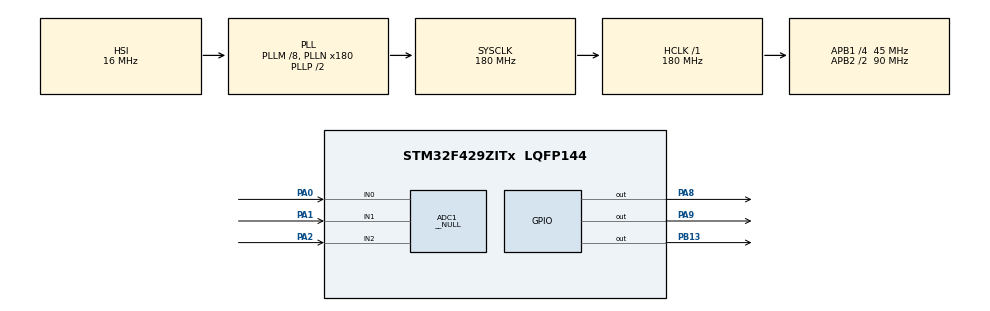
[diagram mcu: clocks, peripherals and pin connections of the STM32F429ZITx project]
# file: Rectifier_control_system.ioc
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ADC1.Channel-0\#ChannelRegularConversion=ADC_CHANNEL_0
ADC1.Channel-3\#ChannelRegularConversion=ADC_CHANNEL_1
ADC1.Channel-4\#ChannelRegularConversion=ADC_CHANNEL_2
ADC1.ContinuousConvMode=ENABLE
ADC1.DMAContinuousRequests=ENABLE
ADC1.EOCSelection=ADC_EOC_SEQ_CONV
ADC1.EnableAnalogWatchDog=true
ADC1.HighThreshold=2189
ADC1.ITMode=ENABLE
ADC1.InjNumberOfConversion=0
ADC1.LowThreshold=2154
ADC1.Mode=__NULL
ADC1.NbrOfConversion=3
ADC1.NbrOfConversionFlag=1
ADC1.Rank-0\#ChannelRegularConversion=1
ADC1.Rank-3\#ChannelRegularConversion=2
ADC1.Rank-4\#ChannelRegularConversion=3
ADC1.SamplingTime-0\#ChannelRegularConversion=ADC_SAMPLETIME_28CYCLES
ADC1.SamplingTime-3\#ChannelRegularConversion=ADC_SAMPLETIME_28CYCLES
ADC1.SamplingTime-4\#ChannelRegularConversion=ADC_SAMPLETIME_28CYCLES
ADC1.ScanConvMode=ENABLE
ADC1.WatchdogMode=ADC_ANALOGWATCHDOG_ALL_REG
ADC1.master=1
Dma.ADC1.0.Direction=DMA_PERIPH_TO_MEMORY
Dma.ADC1.0.FIFOMode=DMA_FIFOMODE_DISABLE
Dma.ADC1.0.Instance=DMA2_Stream0
Dma.ADC1.0.MemDataAlignment=DMA_MDATAALIGN_HALFWORD
Dma.ADC1.0.MemInc=DMA_MINC_ENABLE
Dma.ADC1.0.Mode=DMA_CIRCULAR
Dma.ADC1.0.PeriphDataAlignment=DMA_PDATAALIGN_HALFWORD
Dma.ADC1.0.PeriphInc=DMA_PINC_DISABLE
Dma.ADC1.0.Priority=DMA_PRIORITY_LOW
Dma.Request0=ADC1
Mcu.Family=STM32F4
Mcu.Name=STM32F429ZITx
Mcu.Package=LQFP144
NVIC.ADC_IRQn=true\:0\:0\:false\:false\:true\:true\:true\:true
NVIC.DMA2_Stream0_IRQn=true\:0\:0\:false\:false\:true\:false\:true\:true
NVIC.PriorityGroup=NVIC_PRIORITYGROUP_4
PA0/WKUP.Signal=ADCx_IN0
PA1.Signal=ADCx_IN1
PA13.Mode=Serial_Wire
PA13.Signal=SYS_JTMS-SWDIO
PA14.Mode=Serial_Wire
PA14.Signal=SYS_JTCK-SWCLK
PA2.Signal=ADCx_IN2
PA8.GPIO_PuPd=GPIO_PULLDOWN
PA8.GPIO_Speed=GPIO_SPEED_FREQ_HIGH
PA8.Signal=GPIO_Output
PA9.GPIO_PuPd=GPIO_PULLDOWN
PA9.GPIO_Speed=GPIO_SPEED_FREQ_HIGH
PA9.Signal=GPIO_Output
PB13.GPIO_PuPd=GPIO_PULLDOWN
PB13.GPIO_Speed=GPIO_SPEED_FREQ_HIGH
PB13.Signal=GPIO_Output
PH0/OSC_IN.Mode=HSE-External-Oscillator
PH0/OSC_IN.Signal=RCC_OSC_IN
PH1/OSC_OUT.Mode=HSE-External-Oscillator
PH1/OSC_OUT.Signal=RCC_OSC_OUT
ProjectManager.HeapSize=0x200
ProjectManager.StackSize=0x400
ProjectManager.TargetToolchain=STM32CubeIDE
RCC.48MHZClocksFreq_Value=90000000
RCC.AHBFreq_Value=180000000
RCC.APB1CLKDivider=RCC_HCLK_DIV4
RCC.APB1Freq_Value=45000000
RCC.APB1TimFreq_Value=90000000
RCC.APB2CLKDivider=RCC_HCLK_DIV2
RCC.APB2Freq_Value=90000000
RCC.APB2TimFreq_Value=180000000
RCC.CortexFreq_Value=180000000
RCC.HCLKFreq_Value=180000000
RCC.HSE_VALUE=25000000
RCC.HSI_VALUE=16000000
RCC.LSE_VALUE=32768
RCC.PLLM=8
RCC.PLLN=180
RCC.SYSCLKFreq_VALUE=180000000
RCC.SYSCLKSource=RCC_SYSCLKSOURCE_PLLCLK
RCC.VCOOutputFreq_Value=360000000
SH.ADCx_IN0.0=ADC1_IN0,IN0
SH.ADCx_IN1.0=ADC1_IN1,IN1
SH.ADCx_IN2.0=ADC1_IN2,IN2
board=custom

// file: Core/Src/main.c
/* USER CODE BEGIN Header */
/**
  ******************************************************************************
  * @file           : main.c
  * @brief          : Main program body
  ******************************************************************************
  * @attention
  *
  * Copyright (c) 2025 STMicroelectronics.
  * All rights reserved.
  *
  * This software is licensed under terms that can be found in the LICENSE file
  * in the root directory of this software component.
  * If no LICENSE file comes with this software, it is provided AS-IS.
  *
  ******************************************************************************
  */
/* USER CODE END Header */
#include <adcInit.h>
#include "main.h"

void SystemClock_Config(void);
static void MX_GPIO_Init(void);
static void MX_DMA_Init(void);

int main(void)
{

  /* MCU Configuration--------------------------------------------------------*/

  /* Reset of all peripherals, Initializes the Flash interface and the Systick. */
  HAL_Init();

  /* Configure the system clock */
  SystemClock_Config();

  /* Initialize all configured peripherals */
  MX_GPIO_Init();
  MX_DMA_Init();
  MX_ADC1_Init();
  /* USER CODE BEGIN 2 */
  HAL_ADC_Start_DMA(&hadc1, (uint32_t*)&valueADC_ch, ADC_CHANNELS_NUM);
  /* USER CODE END 2 */

  /* Infinite loop */
  while (1)
  {

  }
}

void SystemClock_Config(void)
{
  RCC_OscInitTypeDef RCC_OscInitStruct = {0};
  RCC_ClkInitTypeDef RCC_ClkInitStruct = {0};

  /** Configure the main internal regulator output voltage
  */
  __HAL_RCC_PWR_CLK_ENABLE();
  __HAL_PWR_VOLTAGESCALING_CONFIG(PWR_REGULATOR_VOLTAGE_SCALE1);

  /** Initializes the RCC Oscillators according to the specified parameters
  * in the RCC_OscInitTypeDef structure.
  */
  RCC_OscInitStruct.OscillatorType = RCC_OSCILLATORTYPE_HSI;
  RCC_OscInitStruct.HSIState = RCC_HSI_ON;
  RCC_OscInitStruct.HSICalibrationValue = RCC_HSICALIBRATION_DEFAULT;
  RCC_OscInitStruct.PLL.PLLState = RCC_PLL_ON;
  RCC_OscInitStruct.PLL.PLLSource = RCC_PLLSOURCE_HSI;
  RCC_OscInitStruct.PLL.PLLM = 8;
  RCC_OscInitStruct.PLL.PLLN = 180;
  RCC_OscInitStruct.PLL.PLLP = RCC_PLLP_DIV2;
  RCC_OscInitStruct.PLL.PLLQ = 4;
  if (HAL_RCC_OscConfig(&RCC_OscInitStruct) != HAL_OK)
  {
    Error_Handler();
  }

  /** Activate the Over-Drive mode
  */
  if (HAL_PWREx_EnableOverDrive() != HAL_OK)
  {
    Error_Handler();
  }

  /** Initializes the CPU, AHB and APB buses clocks
  */
  RCC_ClkInitStruct.ClockType = RCC_CLOCKTYPE_HCLK|RCC_CLOCKTYPE_SYSCLK
                              |RCC_CLOCKTYPE_PCLK1|RCC_CLOCKTYPE_PCLK2;
  RCC_ClkInitStruct.SYSCLKSource = RCC_SYSCLKSOURCE_PLLCLK;
  RCC_ClkInitStruct.AHBCLKDivider = RCC_SYSCLK_DIV1;
  RCC_ClkInitStruct.APB1CLKDivider = RCC_HCLK_DIV4;
  RCC_ClkInitStruct.APB2CLKDivider = RCC_HCLK_DIV2;

  if (HAL_RCC_ClockConfig(&RCC_ClkInitStruct, FLASH_LATENCY_5) != HAL_OK)
  {
    Error_Handler();
  }
}

static void MX_DMA_Init(void)
{

  /* DMA controller clock enable */
  __HAL_RCC_DMA2_CLK_ENABLE();

  /* DMA interrupt init */
  /* DMA2_Stream0_IRQn interrupt configuration */
  HAL_NVIC_SetPriority(DMA2_Stream0_IRQn, 0, 0);
  HAL_NVIC_EnableIRQ(DMA2_Stream0_IRQn);

}

static void MX_GPIO_Init(void)
{
  GPIO_InitTypeDef GPIO_InitStruct = {0};

  /* GPIO Ports Clock Enable */
  __HAL_RCC_GPIOH_CLK_ENABLE();
  __HAL_RCC_GPIOA_CLK_ENABLE();
  __HAL_RCC_GPIOB_CLK_ENABLE();

  /*Configure GPIO pin Output Level */
  HAL_GPIO_WritePin(GPIOB, GPIO_PIN_13, GPIO_PIN_RESET);

  /*Configure GPIO pin Output Level */
  HAL_GPIO_WritePin(GPIOA, GPIO_PIN_8|GPIO_PIN_9, GPIO_PIN_RESET);

  /*Configure GPIO pin : PB13 */
  GPIO_InitStruct.Pin = GPIO_PIN_13;
  GPIO_InitStruct.Mode = GPIO_MODE_OUTPUT_PP;
  GPIO_InitStruct.Pull = GPIO_PULLDOWN;
  GPIO_InitStruct.Speed = GPIO_SPEED_FREQ_HIGH;
  HAL_GPIO_Init(GPIOB, &GPIO_InitStruct);

  /*Configure GPIO pins : PA8 PA9 */
  GPIO_InitStruct.Pin = GPIO_PIN_8|GPIO_PIN_9;
  GPIO_InitStruct.Mode = GPIO_MODE_OUTPUT_PP;
  GPIO_InitStruct.Pull = GPIO_PULLDOWN;
  GPIO_InitStruct.Speed = GPIO_SPEED_FREQ_HIGH;
  HAL_GPIO_Init(GPIOA, &GPIO_InitStruct);

}

/* USER CODE BEGIN 4 */
void HAL_ADC_LevelOutOfWindowCallback(ADC_HandleTypeDef *hadc) {
    if (hadc == &hadc1 && __HAL_ADC_GET_FLAG(hadc, ADC_FLAG_AWD)) {
    	checkChanelns(valueADC_ch, ADC_CHANNELS_NUM);
            __HAL_ADC_CLEAR_FLAG(hadc, ADC_FLAG_AWD);
    }
}
/* USER CODE END 4 */
